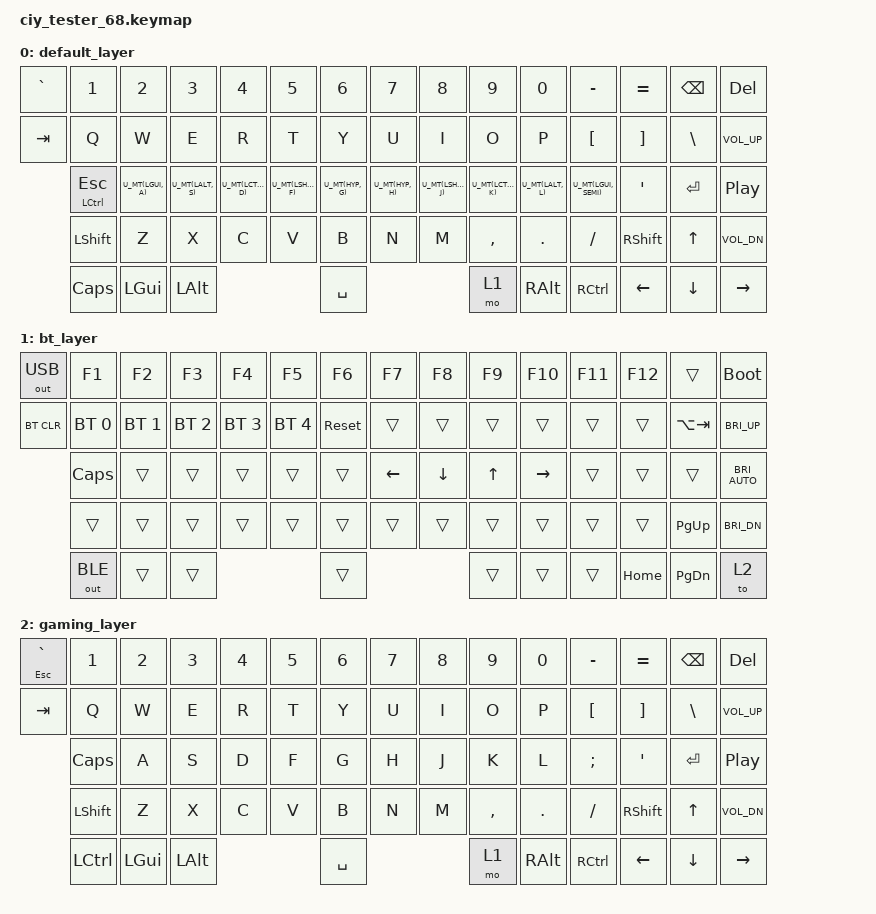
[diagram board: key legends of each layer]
#include <behaviors.dtsi>
#include <dt-bindings/zmk/keys.h>
#include <dt-bindings/zmk/bt.h>
#include <dt-bindings/zmk/outputs.h>

#define U_TAPPING_TERM 200

#include "../../../miryoku/miryoku_behaviours.dtsi"
#include "../../../miryoku/miryoku_behaviours.h"
#include "../../../miryoku/combos.dtsi"

/ {
    keymap {
        compatible = "zmk,keymap";

// ┌───┬───┬───┬───┬───┬───┬───┬───┬───┬───┬───┬───┬───┬───────┬───┐
// │EC`│ 1 │ 2 │ 3 │ 4 │ 5 │ 6 │ 7 │ 8 │ 9 │ 0 │ - │ = │  BACK │DL │
// ├───┴─┬─┴─┬─┴─┬─┴─┬─┴─┬─┴─┬─┴─┬─┴─┬─┴─┬─┴─┬─┴─┬─┴─┬─┴─┬─────┼───┤
// │ TAB │ Q │ W │ E │ R │ T │ Y │ U │ I │ O │ P │ [ │ ] │  \  │V+ │
// ├─────┴┬──┴┬──┴┬──┴┬──┴┬──┴┬──┴┬──┴┬──┴┬──┴┬──┴┬──┴┬──┴─────┼───┤
// │ CAPS │ A │ S │ D │ F │ G │ H │ J │ K │ L │ ; │ ' │ ENTER  │PP │
// ├──────┴─┬─┴─┬─┴─┬─┴─┬─┴─┬─┴─┬─┴─┬─┴─┬─┴─┬─┴─┬─┴─┬─┴────┬───┼───┤
// │ SHIFT  │ Z │ X │ C │ V │ B │ N │ M │ , │ . │ / │SHIFT │UP │V- │
// ├────┬───┴┬──┴─┬─┴───┴───┴───┴───┴───┴──┬┴──┬┴──┬┴──┬───┼───┼───┤
// │CTRL│GUI │ALT │         SPACE          │MOD│ALT│CTL│LFT│DWN│RGT│
// └────┴────┴────┴────────────────────────┴───┴───┴───┴───┴───┴───┘
        default_layer {
            bindings = <
                &kp GRAVE  &kp N1    &kp N2   &kp N3   &kp N4 &kp N5 &kp N6    &kp N7 &kp N8 &kp N9    &kp N0   &kp MINUS &kp EQUAL &kp BSPC &kp DEL
                &kp TAB        &kp Q     &kp W    &kp E    &kp R  &kp T  &kp Y     &kp U  &kp I  &kp O     &kp P    &kp LBKT  &kp RBKT  &kp BSLH &kp C_VOL_UP
                               &mt LCTRL ESC U_MT(LGUI, A)     U_MT(LALT, S) U_MT(LCTRL, D)     U_MT(LSHFT, F)     U_MT(HYP, G)               U_MT(HYP, H)            U_MT(LSHFT, J)     U_MT(LCTRL, K)    U_MT(LALT, L)   U_MT(LGUI, SEMI) &kp SQT   &kp RET  &kp C_PP
                               &kp LSHFT &kp Z    &kp X    &kp C  &kp V  &kp B     &kp N  &kp M  &kp COMMA &kp DOT  &kp FSLH  &kp RSHFT &kp UP   &kp C_VOL_DN
                               &kp CAPS &kp LGUI &kp LALT               &kp SPACE               &mo 1     &kp RALT &kp RCTRL &kp LEFT  &kp DOWN &kp RIGHT
            >;
        };


// ┌───┬───┬───┬───┬───┬───┬───┬───┬───┬───┬───┬───┬───┬───────┬───┐
// │USB│F1 │F2 │F3 │F4 │F5 │F6 │F7 │F8 │F9 │F10│F11│F12│ BACK  │BTL│
// ├───┴─┬─┴─┬─┴─┬─┴─┬─┴─┬─┴─┬─┴─┬─┴─┬─┴─┬─┴─┬─┴─┬─┴─┬─┴─┬─────┼───┤
// │BTCLR│BT0│BT1│BT2│BT3│BT4│RST│ U │ I │ O │ P │ [ │ ] │ALTAB│B+ │
// ├─────┴┬──┴┬──┴┬──┴┬──┴┬──┴┬──┴┬──┴┬──┴┬──┴┬──┴┬──┴┬──┴─────┼───┤
// │ CAPS │ A │ S │ D │ F │ G │HOM│LFT│UP │DWN│RGT│END│ ENTER  │BAT│
// ├──────┴─┬─┴─┬─┴─┬─┴─┬─┴─┬─┴─┬─┴─┬─┴─┬─┴─┬─┴─┬─┴─┬─┴────┬───┼───┤
// │ SHIFT  │ Z │ X │ C │ V │ B │ N │ M │ , │ . │ / │SHIFT │PGU│B- │
// ├────┬───┴┬──┴─┬─┴───┴───┴───┴───┴───┴──┬┴──┬┴──┬┴──┬───┼───┼───┤
// │BLE │GUI │ALT │         SPACE          │MOD│ALT│CTL│HOM│PGD│GME│
// └────┴────┴────┴────────────────────────┴───┴───┴───┴───┴───┴───┘
        bt_layer {
            bindings = <
                &out OUT_USB &kp F1       &kp F2       &kp F3       &kp F4       &kp F5        &kp F6 &kp F7   &kp F8   &kp F9 &kp F10  &kp F11   &kp F12  &trans      &bootloader
                &bt BT_CLR   &bt BT_SEL 0 &bt BT_SEL 1 &bt BT_SEL 2 &bt BT_SEL 3 &bt BT_SEL 4  &sys_reset &trans   &trans   &trans &trans   &trans    &trans   &kp LA(TAB) &kp C_BRI_UP
                             &kp CAPS       &trans       &trans       &trans       &trans        &trans  &kp LEFT &kp DOWN &kp UP &kp RIGHT &trans &trans  &trans      &kp C_BRI_AUTO
                             &trans       &trans       &trans       &trans       &trans        &trans &trans   &trans   &trans &trans   &trans    &trans   &kp PG_UP   &kp C_BRI_DN
                             &out OUT_BLE &trans       &trans                                  &trans                   &trans &trans   &trans    &kp HOME &kp PG_DN   &to 2
            >;
        };

        gaming_layer {
            bindings = <
                &mt ESC GRAVE  &kp N1    &kp N2   &kp N3   &kp N4 &kp N5 &kp N6    &kp N7 &kp N8 &kp N9    &kp N0   &kp MINUS &kp EQUAL &kp BSPC &kp DEL
                &kp TAB        &kp Q     &kp W    &kp E    &kp R  &kp T  &kp Y     &kp U  &kp I  &kp O     &kp P    &kp LBKT  &kp RBKT  &kp BSLH &kp C_VOL_UP
                               &kp CAPS &kp A     &kp S &kp D     &kp F     &kp G               &kp H            &kp J     &kp K    &kp L   &kp SEMI &kp SQT   &kp RET  &kp C_PP
                               &kp LSHFT &kp Z    &kp X    &kp C  &kp V  &kp B     &kp N  &kp M  &kp COMMA &kp DOT  &kp FSLH  &kp RSHFT &kp UP   &kp C_VOL_DN
                                &kp LCTRL &kp LGUI &kp LALT               &kp SPACE               &mo 1     &kp RALT &kp RCTRL &kp LEFT  &kp DOWN &kp RIGHT
            >;
        };
    };
};
